# MDR32F8 register map
Vendor: Milandr; File version: 1.0
CPU: CM4 r1p1, little endian, no MPU, no FPU, 3 interrupt priority bits
Registers are 32-bit, read-write, reset 0x0 unless marked. A register's access mark holds for its fields unless they carry their own. Offsets are from the block's base; [hi:lo] are bit positions; {n}, {i} and the like mark numbered series; 'fields as' and 'values as' point back to an identical list.

## MDR_PORTA — PORTA
Base 0x40080000
Same registers: MDR_PORTB 0x40081000, MDR_PORTC 0x40082000, MDR_PORTD 0x40083000, MDR_PORTE 0x40084000
0x00 KEY — Key lock Register
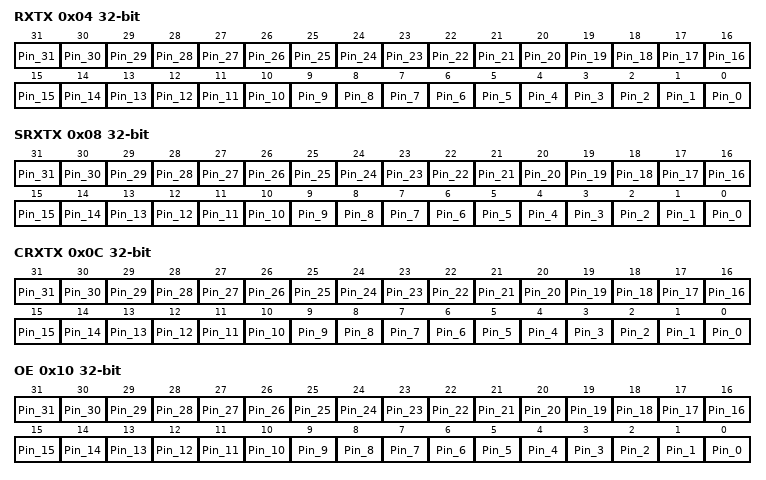
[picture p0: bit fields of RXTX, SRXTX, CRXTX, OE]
0x04 RXTX — GPIO Pin Data Register
  [n] Pin_{n} (n=0..31) — Pin data value
    0=Low (LOW Level Voltage); 1=HIGH Level Voltage
0x08 SRXTX wo — Set RXTX by MASK Register
  [n] Pin_{n} (n=0..31) — Set 1 to pin
    0=Inactive (Do nothing); 1=Selected (Set bit)
0x0C CRXTX wo — Clear RXTX by MASK Register
  [n] Pin_{n} (n=0..31) — Set 0 to pin
    0=Inactive (Do nothing); 1=Selected (Clear bit)
0x10 OE ro — Read SOE: 0 - Input, 1 - Output.
  [n] Pin_{n} (n=0..31) — Read register SOE
    0=IN (Input pin); 1=OUT (Output pin)
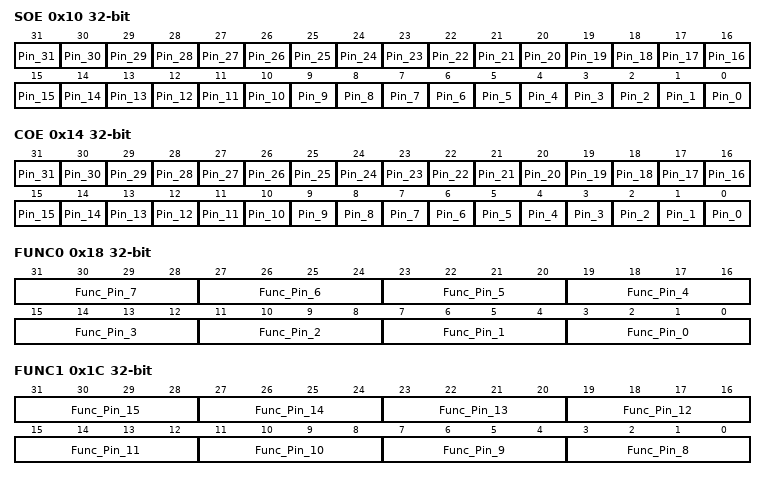
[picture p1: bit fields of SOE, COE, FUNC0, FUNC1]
0x10 SOE wo — Set OE by MASK Register. When reading: 0 - Input, 1 - Output.
  [n] Pin_{n} (n=0..31) — Set pin as output
    0=Inactive (Do nothing); 1=Selected (Set bit)
0x14 COE wo — Clear OE by MASK Register. When reading: 0 - Input, 1 - Output.
  [n] Pin_{n} (n=0..31) write-clears read-clears — Set pin as input
    0=Inactive (Do nothing); 1=Selected (Clear bit)
0x18 FUNC0 ro — Read SFUNC0 Register
  [4n+3:4n] Func_Pin_{n} (n=0..7)
{0x18+4i} SFUNC{i} (i=0..3) — Set FUNC by MASK Register
  [31:0] SFUNC{i} — Set bits of FUNC
0x1C FUNC1 ro — Read SFUNC1 Register
  [4n-29:4n-32] Func_Pin_{n} (n=8..15)
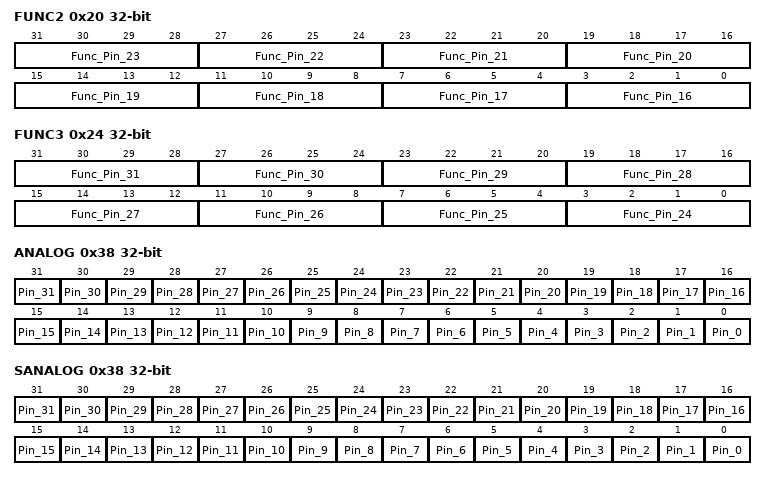
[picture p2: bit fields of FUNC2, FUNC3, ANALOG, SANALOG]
0x20 FUNC2 ro — Read SFUNC2 Register
  [4n-61:4n-64] Func_Pin_{n} (n=16..23)
0x24 FUNC3 ro — Read SFUNC3 Register
  [4n-93:4n-96] Func_Pin_{n} (n=24..31)
{0x28+4i} CFUNC{i} (i=0..3) — Clear FUNC by MASK Register
  [31:0] CFUNC{i} — Clear bits of FUNC
0x38 ANALOG ro — Read SANALOG: 0 - Analog, 1 - Digital.
  [n] Pin_{n} (n=0..31) — Read register SANALOG: 0 - Analog, 1 - Digital.
    0=Analog (Pin works with Analog signal); 1=Digital (Pin works with Digital signal)
0x38 SANALOG wo — Set ANALOG by MASK Register.
  [n] Pin_{n} (n=0..31) — Enable Digital mode
    0=Inactive (Do nothing); 1=Selected (Set bit)
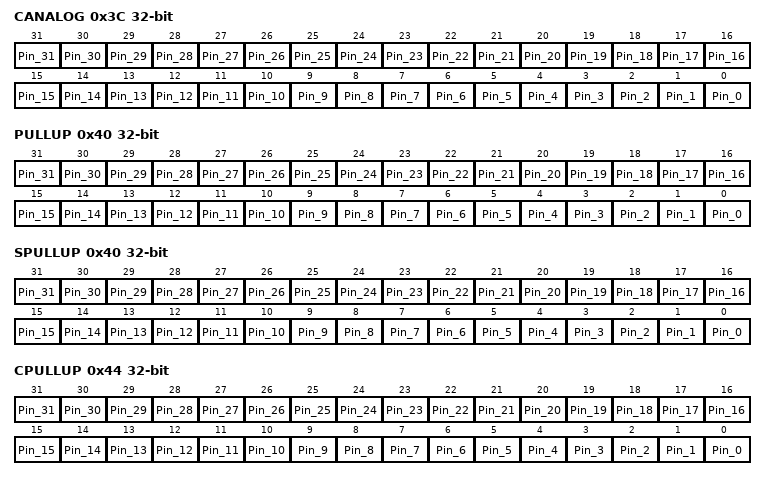
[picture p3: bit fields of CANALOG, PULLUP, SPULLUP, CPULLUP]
0x3C CANALOG wo — Clear ANALOG by MASK Register.
  [n] Pin_{n} (n=0..31) — Enable Analog mode
    0=Inactive (Do nothing); 1=Selected (Clear bit)
0x40 PULLUP ro — Read SPULLUP Register
  [n] Pin_{n} (n=0..31) — Read register SPULLUP
    0=Off (No pull selected); 1=UP (Pin pulled up to VDD)
0x40 SPULLUP wo — Set PULLUP by MASK Register.
  [n] Pin_{n} (n=0..31) — Set pullup
    0=Inactive (Do nothing); 1=Selected (Set bit)
0x44 CPULLUP wo — Clear PULLUP by MASK Register.
  [n] Pin_{n} (n=0..31) — Clear pullup
    0=Inactive (Do nothing); 1=Selected (Clear bit)
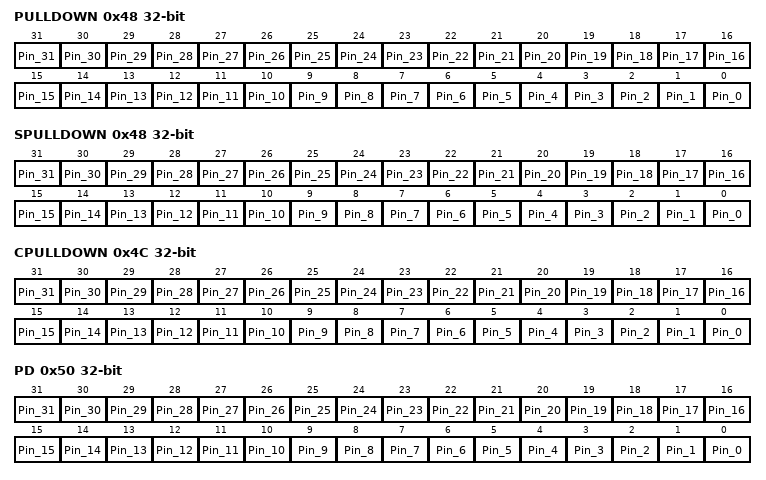
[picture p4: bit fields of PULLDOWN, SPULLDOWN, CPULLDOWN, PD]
0x48 PULLDOWN ro — Read SPULLDOWN Register
  [n] Pin_{n} (n=0..31) — Read register SPULLDOWN
    0=Off (No pull selected); 1=DOWN (Pin pulled down to GND)
0x48 SPULLDOWN wo — Set PULLDOWN by MASK Register.
  [n] Pin_{n} (n=0..31) — Set pulldown
    0=Inactive (Do nothing); 1=Selected (Set bit)
0x4C CPULLDOWN wo — Clear PULLDOWN by MASK Register.
  [n] Pin_{n} (n=0..31) — Clear pulldown
    0=Inactive (Do nothing); 1=Selected (Clear bit)
0x50 PD ro — Read SPD Register
  [n] Pin_{n} (n=0..31) — Read register SPD
    0=Driver (Pull-Push driver); 1=OpenDrain (Work with line pulled up to Ucc)
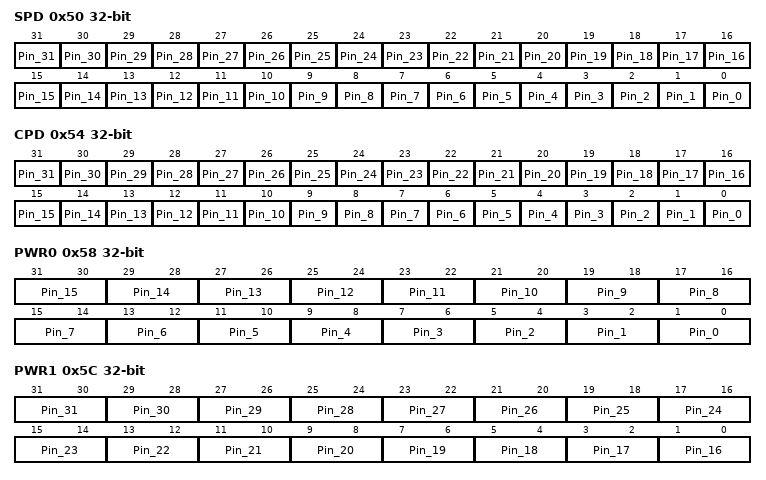
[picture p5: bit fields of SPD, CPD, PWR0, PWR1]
0x50 SPD wo — Set PD by MASK Register.
  [n] Pin_{n} (n=0..31) — Set PD
    0=Inactive (Do nothing); 1=Selected (Set bit)
0x54 CPD wo — Clear PD by MASK Register.
  [n] Pin_{n} (n=0..31) — Clear PD
    0=Inactive (Do nothing); 1=Selected (Clear bit)
0x58 PWR0 ro — Read SPWR0 Register
  [2n+1:2n] Pin_{n} (n=0..15)
    0=Off (Level switch disabled); 1=Slow (Levels switch rate about 300ns); 2=Fast (Levels switch rate about 100ns); 3=MaxFast (Levels switch rate about 10ns)
0x58 SPWR0 — Set PWR by MASK Register
  [31:0] SPWR0 — Set bits of PWR0
0x5C PWR1 ro — Read SPWR1 Register
  [2n-31:2n-32] Pin_{n} (n=16..31)
    values as PWR0.Pin_0
0x5C SPWR1 — Set PWR by MASK Register
  [31:0] SPWR1 — Set bits of PWR1
0x60 CPWR0 — Clear PWR by MASK Register
  [31:0] CPWR0 — Clear bits of PWR0
0x64 CPWR1 — Clear PWR by MASK Register
  [31:0] CPWR1 — Clear bits of PWR1
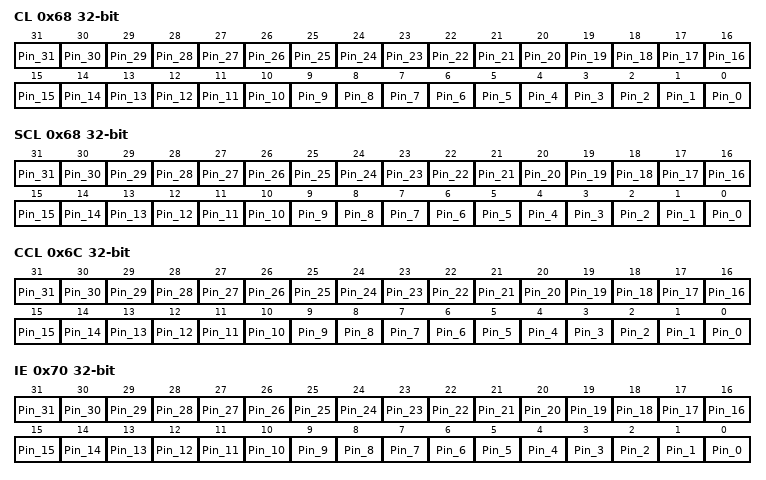
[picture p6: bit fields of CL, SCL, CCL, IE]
0x68 CL ro — Read SCL Register
  [n] Pin_{n} (n=0..31) — Read register SCL
    0=Off (Current control is disabled); 1=On (Current control is enable)
0x68 SCL wo — Set CL by MASK Register.
  [n] Pin_{n} (n=0..31) — Set CL
    0=Inactive (Do nothing); 1=Selected (Set bit)
0x6C CCL wo — Clear CL by MASK Register.
  [n] Pin_{n} (n=0..31) — Clear CL
    0=Inactive (Do nothing); 1=Selected (Clear bit)
0x70 IE ro — Read SIE Register
  [n] Pin_{n} (n=0..31) — Read register SIE
    0=Off (Interrupt disabled); 1=On (Interrupt enable)
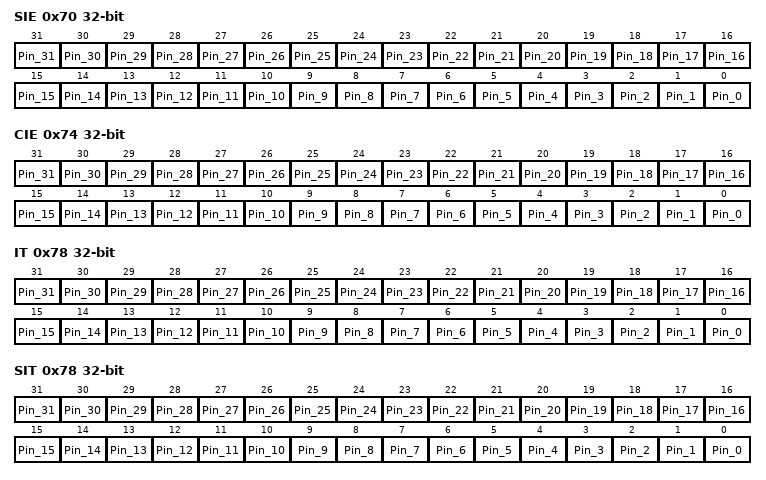
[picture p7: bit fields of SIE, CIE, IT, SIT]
0x70 SIE wo — Set IE by MASK Register.
  [n] Pin_{n} (n=0..31) — Set IE
    0=Inactive (Do nothing); 1=Selected (Set bit)
0x74 CIE wo — Clear IE by MASK Register.
  [n] Pin_{n} (n=0..31) — Clear IE
    0=Inactive (Do nothing); 1=Selected (Clear bit)
0x78 IT ro — Read SIT Register
  [n] Pin_{n} (n=0..31) — Read register SIT
    0=LOW (Fix low level); 1=HIGH (Fix high level)
0x78 SIT wo — Set IT by MASK Register.
  [n] Pin_{n} (n=0..31) — Set IT
    0=Inactive (Do nothing); 1=Selected (Set bit)
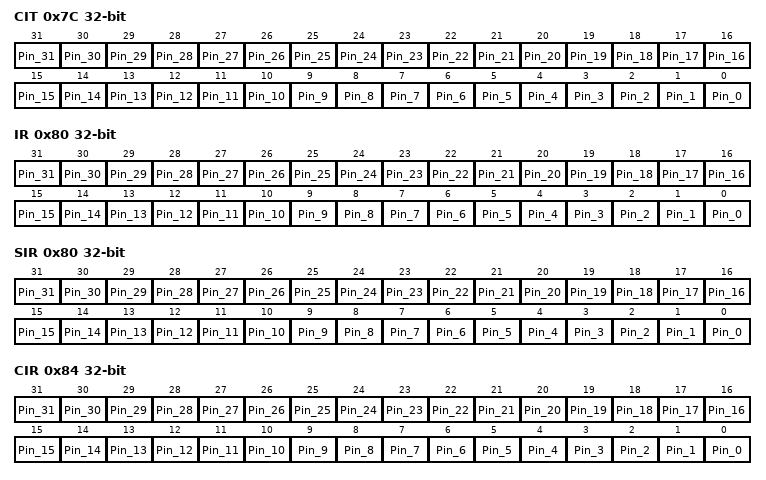
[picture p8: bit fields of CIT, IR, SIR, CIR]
0x7C CIT wo — Clear IT by MASK Register.
  [n] Pin_{n} (n=0..31) — Clear IT
    0=Inactive (Do nothing); 1=Selected (Clear bit)
0x80 IR ro — Read SIR Register
  [n] Pin_{n} (n=0..31) — Read register SIR
    0=Off (Interrupt request is inactive); 1=On (Interrupt request is active)
0x80 SIR wo — Set IR by MASK Register.
  [n] Pin_{n} (n=0..31) — Set IR
    0=Inactive (Do nothing); 1=Selected (Set bit)
0x84 CIR wo — Clear IR by MASK Register.
  [n] Pin_{n} (n=0..31) — Clear IR
    0=Inactive (Do nothing); 1=Selected (Clear bit)
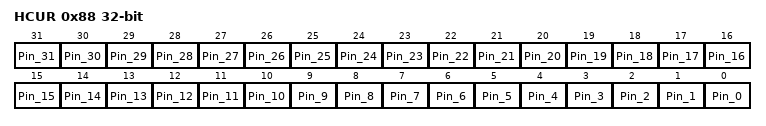
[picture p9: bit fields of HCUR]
0x88 HCUR
  [n] Pin_{n} (n=0..31) — Register HCUR
    0=Off (Overcurrent is inactive); 1=On (Overcurrent is active)
